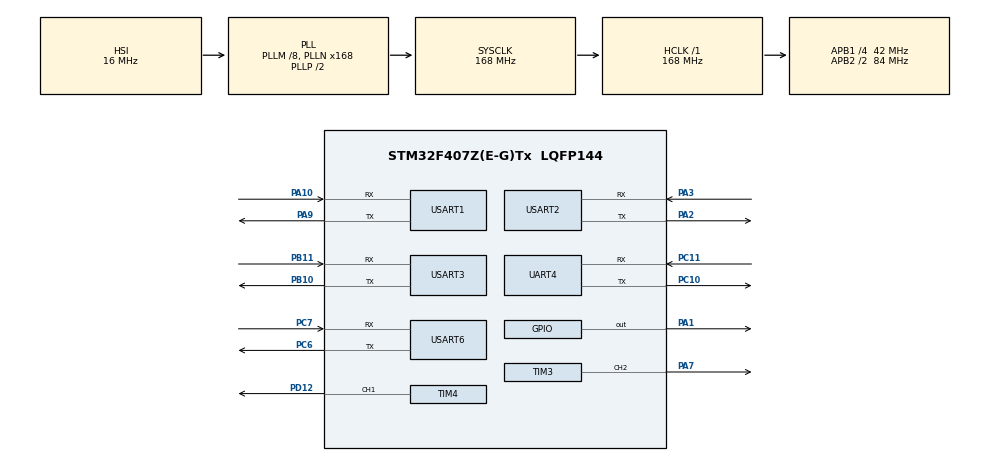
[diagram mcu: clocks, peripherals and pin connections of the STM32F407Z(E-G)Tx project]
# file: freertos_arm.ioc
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Dma.Request0=USART1_RX
Dma.Request1=USART1_TX
Dma.Request10=UART4_TX
Dma.Request2=USART2_RX
Dma.Request3=USART2_TX
Dma.Request4=USART3_RX
Dma.Request5=USART3_TX
Dma.Request6=USART6_RX
Dma.Request7=USART6_TX
Dma.Request8=TIM4_CH1
Dma.Request9=UART4_RX
Dma.TIM4_CH1.8.Direction=DMA_PERIPH_TO_MEMORY
Dma.TIM4_CH1.8.FIFOMode=DMA_FIFOMODE_DISABLE
Dma.TIM4_CH1.8.Instance=DMA1_Stream0
Dma.TIM4_CH1.8.MemDataAlignment=DMA_MDATAALIGN_HALFWORD
Dma.TIM4_CH1.8.MemInc=DMA_MINC_ENABLE
Dma.TIM4_CH1.8.Mode=DMA_NORMAL
Dma.TIM4_CH1.8.PeriphDataAlignment=DMA_PDATAALIGN_HALFWORD
Dma.TIM4_CH1.8.PeriphInc=DMA_PINC_DISABLE
Dma.TIM4_CH1.8.Priority=DMA_PRIORITY_LOW
Dma.UART4_RX.9.Direction=DMA_PERIPH_TO_MEMORY
Dma.UART4_RX.9.FIFOMode=DMA_FIFOMODE_DISABLE
Dma.UART4_RX.9.Instance=DMA1_Stream2
Dma.UART4_RX.9.MemDataAlignment=DMA_MDATAALIGN_BYTE
Dma.UART4_RX.9.MemInc=DMA_MINC_ENABLE
Dma.UART4_RX.9.Mode=DMA_NORMAL
Dma.UART4_RX.9.PeriphDataAlignment=DMA_PDATAALIGN_BYTE
Dma.UART4_RX.9.PeriphInc=DMA_PINC_DISABLE
Dma.UART4_RX.9.Priority=DMA_PRIORITY_LOW
Dma.UART4_TX.10.Direction=DMA_MEMORY_TO_PERIPH
Dma.UART4_TX.10.FIFOMode=DMA_FIFOMODE_DISABLE
Dma.UART4_TX.10.Instance=DMA1_Stream4
Dma.UART4_TX.10.MemDataAlignment=DMA_MDATAALIGN_BYTE
Dma.UART4_TX.10.MemInc=DMA_MINC_ENABLE
Dma.UART4_TX.10.Mode=DMA_NORMAL
Dma.UART4_TX.10.PeriphDataAlignment=DMA_PDATAALIGN_BYTE
Dma.UART4_TX.10.PeriphInc=DMA_PINC_DISABLE
Dma.UART4_TX.10.Priority=DMA_PRIORITY_LOW
Dma.USART1_RX.0.Direction=DMA_PERIPH_TO_MEMORY
Dma.USART1_RX.0.FIFOMode=DMA_FIFOMODE_DISABLE
Dma.USART1_RX.0.Instance=DMA2_Stream2
Dma.USART1_RX.0.MemDataAlignment=DMA_MDATAALIGN_BYTE
Dma.USART1_RX.0.MemInc=DMA_MINC_ENABLE
Dma.USART1_RX.0.Mode=DMA_NORMAL
Dma.USART1_RX.0.PeriphDataAlignment=DMA_PDATAALIGN_BYTE
Dma.USART1_RX.0.PeriphInc=DMA_PINC_DISABLE
Dma.USART1_RX.0.Priority=DMA_PRIORITY_LOW
Dma.USART1_TX.1.Direction=DMA_MEMORY_TO_PERIPH
Dma.USART1_TX.1.FIFOMode=DMA_FIFOMODE_DISABLE
Dma.USART1_TX.1.Instance=DMA2_Stream7
Dma.USART1_TX.1.MemDataAlignment=DMA_MDATAALIGN_BYTE
Dma.USART1_TX.1.MemInc=DMA_MINC_ENABLE
Dma.USART1_TX.1.Mode=DMA_NORMAL
Dma.USART1_TX.1.PeriphDataAlignment=DMA_PDATAALIGN_BYTE
Dma.USART1_TX.1.PeriphInc=DMA_PINC_DISABLE
Dma.USART1_TX.1.Priority=DMA_PRIORITY_LOW
Dma.USART2_RX.2.Direction=DMA_PERIPH_TO_MEMORY
Dma.USART2_RX.2.FIFOMode=DMA_FIFOMODE_DISABLE
Dma.USART2_RX.2.Instance=DMA1_Stream5
Dma.USART2_RX.2.MemDataAlignment=DMA_MDATAALIGN_BYTE
Dma.USART2_RX.2.MemInc=DMA_MINC_ENABLE
Dma.USART2_RX.2.Mode=DMA_NORMAL
Dma.USART2_RX.2.PeriphDataAlignment=DMA_PDATAALIGN_BYTE
Dma.USART2_RX.2.PeriphInc=DMA_PINC_DISABLE
Dma.USART2_RX.2.Priority=DMA_PRIORITY_LOW
Dma.USART2_TX.3.Direction=DMA_MEMORY_TO_PERIPH
Dma.USART2_TX.3.FIFOMode=DMA_FIFOMODE_DISABLE
Dma.USART2_TX.3.Instance=DMA1_Stream6
Dma.USART2_TX.3.MemDataAlignment=DMA_MDATAALIGN_BYTE
Dma.USART2_TX.3.MemInc=DMA_MINC_ENABLE
Dma.USART2_TX.3.Mode=DMA_NORMAL
Dma.USART2_TX.3.PeriphDataAlignment=DMA_PDATAALIGN_BYTE
Dma.USART2_TX.3.PeriphInc=DMA_PINC_DISABLE
Dma.USART2_TX.3.Priority=DMA_PRIORITY_LOW
Dma.USART3_RX.4.Direction=DMA_PERIPH_TO_MEMORY
Dma.USART3_RX.4.FIFOMode=DMA_FIFOMODE_DISABLE
Dma.USART3_RX.4.Instance=DMA1_Stream1
Dma.USART3_RX.4.MemDataAlignment=DMA_MDATAALIGN_BYTE
Dma.USART3_RX.4.MemInc=DMA_MINC_ENABLE
Dma.USART3_RX.4.Mode=DMA_NORMAL
Dma.USART3_RX.4.PeriphDataAlignment=DMA_PDATAALIGN_BYTE
Dma.USART3_RX.4.PeriphInc=DMA_PINC_DISABLE
Dma.USART3_RX.4.Priority=DMA_PRIORITY_LOW
Dma.USART3_TX.5.Direction=DMA_MEMORY_TO_PERIPH
Dma.USART3_TX.5.FIFOMode=DMA_FIFOMODE_DISABLE
Dma.USART3_TX.5.Instance=DMA1_Stream3
Dma.USART3_TX.5.MemDataAlignment=DMA_MDATAALIGN_BYTE
Dma.USART3_TX.5.MemInc=DMA_MINC_ENABLE
Dma.USART3_TX.5.Mode=DMA_NORMAL
Dma.USART3_TX.5.PeriphDataAlignment=DMA_PDATAALIGN_BYTE
Dma.USART3_TX.5.PeriphInc=DMA_PINC_DISABLE
Dma.USART3_TX.5.Priority=DMA_PRIORITY_LOW
Dma.USART6_RX.6.Direction=DMA_PERIPH_TO_MEMORY
Dma.USART6_RX.6.FIFOMode=DMA_FIFOMODE_DISABLE
Dma.USART6_RX.6.Instance=DMA2_Stream1
Dma.USART6_RX.6.MemDataAlignment=DMA_MDATAALIGN_BYTE
Dma.USART6_RX.6.MemInc=DMA_MINC_ENABLE
Dma.USART6_RX.6.Mode=DMA_NORMAL
Dma.USART6_RX.6.PeriphDataAlignment=DMA_PDATAALIGN_BYTE
Dma.USART6_RX.6.PeriphInc=DMA_PINC_DISABLE
Dma.USART6_RX.6.Priority=DMA_PRIORITY_LOW
Dma.USART6_TX.7.Direction=DMA_MEMORY_TO_PERIPH
Dma.USART6_TX.7.FIFOMode=DMA_FIFOMODE_DISABLE
Dma.USART6_TX.7.Instance=DMA2_Stream6
Dma.USART6_TX.7.MemDataAlignment=DMA_MDATAALIGN_BYTE
Dma.USART6_TX.7.MemInc=DMA_MINC_ENABLE
Dma.USART6_TX.7.Mode=DMA_NORMAL
Dma.USART6_TX.7.PeriphDataAlignment=DMA_PDATAALIGN_BYTE
Dma.USART6_TX.7.PeriphInc=DMA_PINC_DISABLE
Dma.USART6_TX.7.Priority=DMA_PRIORITY_LOW
FREERTOS.Tasks01=defaultTask,24,128,StartDefaultTask,Default,NULL,Dynamic,NULL,NULL;task1,24,1000,task1_start,Default,NULL,Dynamic,NULL,NULL;task2,12,1000,task2_start,Default,NULL,Dynamic,NULL,NULL;task3,8,1000,task3_start,Default,NULL,Dynamic,NULL,NULL;first_task,47,128,first_task_begin,Default,NULL,Dynamic,NULL,NULL
FREERTOS.configTOTAL_HEAP_SIZE=20000
Mcu.Family=STM32F4
Mcu.Name=STM32F407Z(E-G)Tx
Mcu.Package=LQFP144
NVIC.DMA1_Stream0_IRQn=true\:5\:0\:false\:false\:true\:true\:false\:true\:true
NVIC.DMA1_Stream1_IRQn=true\:5\:0\:false\:false\:true\:true\:false\:true\:true
NVIC.DMA1_Stream2_IRQn=true\:5\:0\:false\:false\:true\:true\:false\:true\:true
NVIC.DMA1_Stream3_IRQn=true\:5\:0\:false\:false\:true\:true\:false\:true\:true
NVIC.DMA1_Stream4_IRQn=true\:5\:0\:false\:false\:true\:true\:false\:true\:true
NVIC.DMA1_Stream5_IRQn=true\:5\:0\:false\:false\:true\:true\:false\:true\:true
NVIC.DMA1_Stream6_IRQn=true\:5\:0\:false\:false\:true\:true\:false\:true\:true
NVIC.DMA2_Stream1_IRQn=true\:5\:0\:false\:false\:true\:true\:false\:true\:true
NVIC.DMA2_Stream2_IRQn=true\:5\:0\:false\:false\:true\:true\:false\:true\:true
NVIC.DMA2_Stream6_IRQn=true\:5\:0\:false\:false\:true\:true\:false\:true\:true
NVIC.DMA2_Stream7_IRQn=true\:5\:0\:false\:false\:true\:true\:false\:true\:true
NVIC.PriorityGroup=NVIC_PRIORITYGROUP_4
NVIC.TIM1_UP_TIM10_IRQn=true\:15\:0\:true\:false\:true\:false\:false\:true\:true
NVIC.TIM2_IRQn=true\:5\:0\:false\:false\:true\:true\:true\:true\:true
NVIC.TIM4_IRQn=true\:5\:0\:false\:false\:true\:true\:true\:true\:true
NVIC.TimeBase=TIM1_UP_TIM10_IRQn
NVIC.TimeBaseIP=TIM1
NVIC.UART4_IRQn=true\:5\:0\:false\:false\:true\:true\:true\:true\:true
NVIC.USART1_IRQn=true\:6\:0\:true\:false\:true\:true\:true\:true\:true
NVIC.USART2_IRQn=true\:5\:0\:false\:false\:true\:true\:true\:true\:true
NVIC.USART3_IRQn=true\:5\:0\:false\:false\:true\:true\:true\:true\:true
NVIC.USART6_IRQn=true\:5\:0\:false\:false\:true\:true\:true\:true\:true
PA1.Signal=GPIO_Output
PA10.Mode=Asynchronous
PA10.Signal=USART1_RX
PA13.Mode=Serial_Wire
PA13.Signal=SYS_JTMS-SWDIO
PA14.Mode=Serial_Wire
PA14.Signal=SYS_JTCK-SWCLK
PA2.Mode=Asynchronous
PA2.Signal=USART2_TX
PA3.Mode=Asynchronous
PA3.Signal=USART2_RX
PA7.Signal=S_TIM3_CH2
PA9.Mode=Asynchronous
PA9.Signal=USART1_TX
PB10.Mode=Asynchronous
PB10.Signal=USART3_TX
PB11.Mode=Asynchronous
PB11.Signal=USART3_RX
PC10.Mode=Asynchronous
PC10.Signal=UART4_TX
PC11.Mode=Asynchronous
PC11.Signal=UART4_RX
PC14-OSC32_IN.Mode=LSE-External-Clock-Source
PC14-OSC32_IN.Signal=RCC_OSC32_IN
PC15-OSC32_OUT.Mode=LSE-External-Clock-Source
PC15-OSC32_OUT.Signal=RCC_OSC32_OUT
PC6.Mode=Asynchronous
PC6.Signal=USART6_TX
PC7.Mode=Asynchronous
PC7.Signal=USART6_RX
PD12.Signal=S_TIM4_CH1
PH0-OSC_IN.Mode=HSE-External-Clock-Source
PH0-OSC_IN.Signal=RCC_OSC_IN
PH1-OSC_OUT.Mode=HSE-External-Clock-Source
PH1-OSC_OUT.Signal=RCC_OSC_OUT
ProjectManager.HeapSize=0x200
ProjectManager.StackSize=0x400
ProjectManager.TargetToolchain=MDK-ARM V5.32
RCC.48MHZClocksFreq_Value=84000000
RCC.AHBFreq_Value=168000000
RCC.APB1CLKDivider=RCC_HCLK_DIV4
RCC.APB1Freq_Value=42000000
RCC.APB1TimFreq_Value=84000000
RCC.APB2CLKDivider=RCC_HCLK_DIV2
RCC.APB2Freq_Value=84000000
RCC.APB2TimFreq_Value=168000000
RCC.CortexFreq_Value=168000000
RCC.HCLKFreq_Value=168000000
RCC.HSE_VALUE=25000000
RCC.HSI_VALUE=16000000
RCC.LSE_VALUE=32768
RCC.PLLM=8
RCC.PLLN=168
RCC.SYSCLKFreq_VALUE=168000000
RCC.SYSCLKSource=RCC_SYSCLKSOURCE_PLLCLK
RCC.VCOOutputFreq_Value=336000000
SH.S_TIM3_CH2.0=TIM3_CH2,PWM Generation2 CH2
SH.S_TIM4_CH1.0=TIM4_CH1,PWM Generation1 CH1
STMicroelectronics.X-CUBE-ALGOBUILD.1.3.0.LibraryCcDSPOoLibraryJjDSPOoLibrary=true
TIM2.AutoReloadPreload=TIM_AUTORELOAD_PRELOAD_ENABLE
TIM2.Period=5000
TIM2.Prescaler=167
TIM2.TIM_MasterOutputTrigger=TIM_TRGO_RESET
TIM3.AutoReloadPreload=TIM_AUTORELOAD_PRELOAD_ENABLE
TIM3.Channel-PWM\ Generation2\ CH2=TIM_CHANNEL_2
TIM3.Period=20000
TIM3.Prescaler=167
TIM3.TIM_MasterOutputTrigger=TIM_TRGO_ENABLE
TIM4.AutoReloadPreload=TIM_AUTORELOAD_PRELOAD_ENABLE
TIM4.Channel-PWM\ Generation1\ CH1=TIM_CHANNEL_1
TIM4.Period=1000
TIM4.Prescaler=167
TIM4.TIM_MasterOutputTrigger=TIM_TRGO_ENABLE
UART4.VirtualMode=Asynchronous
USART1.VirtualMode=VM_ASYNC
USART2.VirtualMode=VM_ASYNC
USART3.VirtualMode=VM_ASYNC
USART6.VirtualMode=VM_ASYNC
VP_FREERTOS_VS_CMSIS_V2.Mode=CMSIS_V2
VP_STMicroelectronics.X-CUBE-ALGOBUILD_VS_DSPOoLibraryJjLibrary_1.3.0_1.3.0.Mode=DSPOoLibraryJjLibrary
VP_SYS_VS_tim1.Mode=TIM1
VP_TIM2_VS_ClockSourceINT.Mode=Internal
VP_TIM4_VS_ClockSourceINT.Mode=Internal
board=custom

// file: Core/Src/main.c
/* USER CODE BEGIN Header */
/**
 ******************************************************************************
 * @file           : main.c
 * @brief          : Main program body
 ******************************************************************************
 * @attention
 *
 * Copyright (c) 2023 STMicroelectronics.
 * All rights reserved.
 *
 * This software is licensed under terms that can be found in the LICENSE file
 * in the root directory of this software component.
 * If no LICENSE file comes with this software, it is provided AS-IS.
 *
 ******************************************************************************
 */
/* USER CODE END Header */
#include "main.h"
#include "cmsis_os.h"
#include "dma.h"
#include "tim.h"
#include "usart.h"
#include "gpio.h"

/* USER CODE BEGIN Includes */
#include "MyProject.h"
/* USER CODE END Includes */

void SystemClock_Config(void);
void MX_FREERTOS_Init(void);
/* USER CODE BEGIN PFP */
extern int move_cnt;
/* USER CODE END PFP */

int main(void)
{

  /* MCU Configuration--------------------------------------------------------*/

  /* Reset of all peripherals, Initializes the Flash interface and the Systick. */
  HAL_Init();

  /* Configure the system clock */
  SystemClock_Config();

  /* Initialize all configured peripherals */
  MX_GPIO_Init();
  MX_DMA_Init();
  MX_USART1_UART_Init();
  MX_USART2_UART_Init();
  MX_USART3_UART_Init();
  MX_USART6_UART_Init();
  MX_TIM2_Init();
  MX_TIM3_Init();
  MX_TIM4_Init();
  MX_UART4_Init();
  /* USER CODE BEGIN 2 */
  printf("��е�ۣ�������\r\n");
  /* USER CODE END 2 */

  /* Init scheduler */
  osKernelInitialize(); /* Call init function for freertos objects (in freertos.c) */
  MX_FREERTOS_Init();

  /* Start scheduler */
  osKernelStart();

  /* We should never get here as control is now taken by the scheduler */
  /* Infinite loop */
  while (1)
  {

  }
}

void SystemClock_Config(void)
{
  RCC_OscInitTypeDef RCC_OscInitStruct = {0};
  RCC_ClkInitTypeDef RCC_ClkInitStruct = {0};

  /** Configure the main internal regulator output voltage
   */
  __HAL_RCC_PWR_CLK_ENABLE();
  __HAL_PWR_VOLTAGESCALING_CONFIG(PWR_REGULATOR_VOLTAGE_SCALE1);

  /** Initializes the RCC Oscillators according to the specified parameters
   * in the RCC_OscInitTypeDef structure.
   */
  RCC_OscInitStruct.OscillatorType = RCC_OSCILLATORTYPE_HSI;
  RCC_OscInitStruct.HSIState = RCC_HSI_ON;
  RCC_OscInitStruct.HSICalibrationValue = RCC_HSICALIBRATION_DEFAULT;
  RCC_OscInitStruct.PLL.PLLState = RCC_PLL_ON;
  RCC_OscInitStruct.PLL.PLLSource = RCC_PLLSOURCE_HSI;
  RCC_OscInitStruct.PLL.PLLM = 8;
  RCC_OscInitStruct.PLL.PLLN = 168;
  RCC_OscInitStruct.PLL.PLLP = RCC_PLLP_DIV2;
  RCC_OscInitStruct.PLL.PLLQ = 4;
  if (HAL_RCC_OscConfig(&RCC_OscInitStruct) != HAL_OK)
  {
    Error_Handler();
  }

  /** Initializes the CPU, AHB and APB buses clocks
   */
  RCC_ClkInitStruct.ClockType = RCC_CLOCKTYPE_HCLK | RCC_CLOCKTYPE_SYSCLK | RCC_CLOCKTYPE_PCLK1 | RCC_CLOCKTYPE_PCLK2;
  RCC_ClkInitStruct.SYSCLKSource = RCC_SYSCLKSOURCE_PLLCLK;
  RCC_ClkInitStruct.AHBCLKDivider = RCC_SYSCLK_DIV1;
  RCC_ClkInitStruct.APB1CLKDivider = RCC_HCLK_DIV4;
  RCC_ClkInitStruct.APB2CLKDivider = RCC_HCLK_DIV2;

  if (HAL_RCC_ClockConfig(&RCC_ClkInitStruct, FLASH_LATENCY_5) != HAL_OK)
  {
    Error_Handler();
  }
}

void HAL_TIM_PeriodElapsedCallback(TIM_HandleTypeDef *htim)
{
  if (htim->Instance == TIM1)
  {
    HAL_IncTick();
  }
}

void Error_Handler(void)
{
  __disable_irq();
  while (1)
  {
  }
}

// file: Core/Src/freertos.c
/* USER CODE BEGIN Header */
/**
 ******************************************************************************
 * File Name          : freertos.c
 * Description        : Code for freertos applications
 ******************************************************************************
 * @attention
 *
 * Copyright (c) 2023 STMicroelectronics.
 * All rights reserved.
 *
 * This software is licensed under terms that can be found in the LICENSE file
 * in the root directory of this software component.
 * If no LICENSE file comes with this software, it is provided AS-IS.
 *
 ******************************************************************************
 */
/* USER CODE END Header */

#include "FreeRTOS.h"
#include "task.h"
#include "main.h"
#include "cmsis_os.h"

/* USER CODE BEGIN Includes */
#include <MyProject.h>
/* USER CODE END Includes */

/* Definitions for defaultTask */
osThreadId_t defaultTaskHandle;
const osThreadAttr_t defaultTask_attributes = {
  .name = "defaultTask",
  .stack_size = 128 * 4,
  .priority = (osPriority_t) osPriorityNormal,
};
/* Definitions for task1 */
osThreadId_t task1Handle;
const osThreadAttr_t task1_attributes = {
  .name = "task1",
  .stack_size = 1000 * 4,
  .priority = (osPriority_t) osPriorityNormal,
};
/* Definitions for task2 */
osThreadId_t task2Handle;
const osThreadAttr_t task2_attributes = {
  .name = "task2",
  .stack_size = 1000 * 4,
  .priority = (osPriority_t) osPriorityLow4,
};
/* Definitions for task3 */
osThreadId_t task3Handle;
const osThreadAttr_t task3_attributes = {
  .name = "task3",
  .stack_size = 1000 * 4,
  .priority = (osPriority_t) osPriorityLow,
};
/* Definitions for first_task */
osThreadId_t first_taskHandle;
const osThreadAttr_t first_task_attributes = {
  .name = "first_task",
  .stack_size = 128 * 4,
  .priority = (osPriority_t) osPriorityHigh7,
};

void StartDefaultTask(void *argument);
void task1_start(void *argument);
void task2_start(void *argument);
void task3_start(void *argument);
void first_task_begin(void *argument);

void MX_FREERTOS_Init(void); /* (MISRA C 2004 rule 8.1) */

void MX_FREERTOS_Init(void) {

  /* Create the thread(s) */
  /* creation of defaultTask */
  defaultTaskHandle = osThreadNew(StartDefaultTask, NULL, &defaultTask_attributes);

  /* creation of task1 */
  task1Handle = osThreadNew(task1_start, NULL, &task1_attributes);

  /* creation of task2 */
  task2Handle = osThreadNew(task2_start, NULL, &task2_attributes);

  /* creation of task3 */
  task3Handle = osThreadNew(task3_start, NULL, &task3_attributes);

  /* creation of first_task */
  first_taskHandle = osThreadNew(first_task_begin, NULL, &first_task_attributes);

}

void StartDefaultTask(void *argument)
{
  for (;;)
  {
    osDelay(1);
  }
}

void task1_start(void *argument)
{
  /* USER CODE BEGIN task1_start */
  /* Infinite loop */
  for (;;)
  {
    vTaskSuspend(task2Handle);
    task1();
    osDelay(1);
  }
  /* USER CODE END task1_start */
}

void task2_start(void *argument)
{
  /* USER CODE BEGIN task2_start */
  /* Infinite loop */
  for (;;)
  {
    // printf("ИООс¶юЅвРь\r\n");
    task2();
    osDelay(1);
    // vTaskSuspend(NULL);
  }
  /* USER CODE END task2_start */
}

void task3_start(void *argument)
{
  /* USER CODE BEGIN task3_start */
  /* Infinite loop */
  for (;;)
  {
    task3();
    osDelay(1);
    vTaskSuspend(NULL);

    // osDelay(1);
  }
  /* USER CODE END task3_start */
}

void first_task_begin(void *argument)
{
  /* USER CODE BEGIN first_task_begin */
  /* Infinite loop */
  for (;;)
  {
    init_my_project();
    vTaskSuspend(task1Handle);
    vTaskSuspend(task2Handle);
    vTaskSuspend(task3Handle);
    osDelay(1);
    vTaskSuspend(NULL);
  }
  /* USER CODE END first_task_begin */
}
